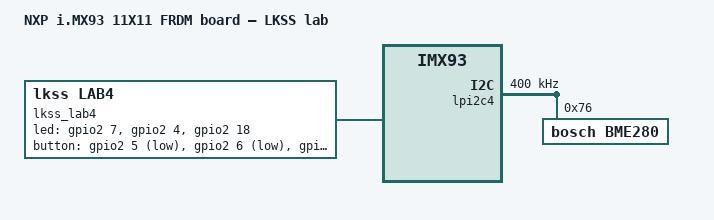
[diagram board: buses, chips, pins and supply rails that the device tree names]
// SPDX-License-Identifier: (GPL-2.0+ OR MIT)
/*
 * imx93-11x11-frdm-lkss.dts – LKSS lab device tree for NXP i.MX93 FRDM board
 *
 * Extends the upstream imx93-11x11-frdm.dts with two lab peripherals:
 *
 *   1. Bosch BME280 environmental sensor on LPI2C4
 *      – I2C address: 0x76 (SDO tied to GND)
 *      – SDA: GPIO_IO02 / EXT2 pin 3
 *      – SCL: GPIO_IO03 / EXT2 pin 5
 *
 *   2. Three GPIO-controlled LEDs (active-high, 220 Ω series resistor)
 *      – LED0 (red):   GPIO_IO07 / GPIO2_IO07 / EXT2 pin 26
 *      – LED1 (green): GPIO_IO04 / GPIO2_IO04 / EXT2 pin  7
 *      – LED2 (blue):  GPIO_IO18 / GPIO2_IO18 / EXT2 pin 12
 *
 *   3. Four GPIO push-buttons (active-low, external pull-ups to 3V3 required)
 *      – BTN1: GPIO_IO05 / GPIO2_IO05 / EXT2 pin 29
 *      – BTN2: GPIO_IO06 / GPIO2_IO06 / EXT2 pin 31
 *      – BTN3: GPIO_IO00 / GPIO2_IO00 / EXT2 pin 27
 *      – BTN4: GPIO_IO01 / GPIO2_IO01 / EXT2 pin 28
 *
 * Build:
 *   Add 'dtb-$(CONFIG_ARCH_MXC) += imx93-11x11-frdm-lkss.dtb' to
 *   arch/arm64/boot/dts/freescale/Makefile and rebuild with:
 *     make dtbs ARCH=arm64 CROSS_COMPILE=aarch64-linux-gnu-
 */

/dts-v1/;

#include "imx93-11x11-frdm.dts"

/ {
	model = "NXP i.MX93 11X11 FRDM board – LKSS lab";
	compatible = "fsl,imx93-11x11-frdm-lkss", "fsl,imx93-11x11-frdm", "fsl,imx93";

	/*
	 * lkss-lab4 – Lab 4 platform device (platform_gpio.ko).
	 *
	 * led-gpios and button-gpios use the GPIO descriptor consumer API:
	 * property "<name>-gpios", driver calls devm_gpiod_get_index(dev, "<name>", idx, flags).
	 * GPIO_ACTIVE_HIGH/LOW encodes polarity; gpiod handles inversion automatically.
	 */
	lkss_lab4: lkss-lab4 {
		compatible = "lkss,lab4";

		led-gpios = <&gpio2  7 GPIO_ACTIVE_HIGH>,  /* LED0 red   / pin 26 */
		            <&gpio2  4 GPIO_ACTIVE_HIGH>,  /* LED1 green / pin  7 */
		            <&gpio2 18 GPIO_ACTIVE_HIGH>;  /* LED2 blue  / pin 12 */

		/*
		 * Active-low: pressing pulls the line to GND.
		 * External 10 kΩ pull-ups to 3V3 required on each line.
		 */
		button-gpios = <&gpio2 5 GPIO_ACTIVE_LOW>,   /* BTN1 / pin 29 */
		               <&gpio2 6 GPIO_ACTIVE_LOW>,   /* BTN2 / pin 31 */
		               <&gpio2 0 GPIO_ACTIVE_LOW>,   /* BTN3 / pin 27 */
		               <&gpio2 1 GPIO_ACTIVE_LOW>;   /* BTN4 / pin 28 */

		pinctrl-names = "default";
		pinctrl-0 = <&pinctrl_lkss_gpio>;
		status = "okay";
	};

	/*
	 * lkss-gpio – reference implementation (lkss_gpio.ko, simple on/off).
	 * Disabled: lkss-lab4 claims the same GPIO lines.
	 * To use: set lkss-lab4 status = "disabled" and this to "okay".
	 */
	lkss_gpio: lkss-gpio {
		compatible = "lkss,gpio-demo";

		led-gpios = <&gpio2  7 GPIO_ACTIVE_HIGH>,  /* LED0 red   / pin 26 */
		            <&gpio2  4 GPIO_ACTIVE_HIGH>,  /* LED1 green / pin  7 */
		            <&gpio2 18 GPIO_ACTIVE_HIGH>;  /* LED2 blue  / pin 12 */

		button-gpios = <&gpio2 5 GPIO_ACTIVE_LOW>,   /* BTN1 / pin 29 */
		               <&gpio2 6 GPIO_ACTIVE_LOW>,   /* BTN2 / pin 31 */
		               <&gpio2 0 GPIO_ACTIVE_LOW>,   /* BTN3 / pin 27 */
		               <&gpio2 1 GPIO_ACTIVE_LOW>;   /* BTN4 / pin 28 */

		pinctrl-names = "default";
		pinctrl-0 = <&pinctrl_lkss_gpio>;
		status = "disabled";
	};
};

/* ── BME280 sensor on LPI2C4 ─────────────────────────────────────────────── */

&lpi2c4 {
	clock-frequency = <400000>;
	pinctrl-names = "default";
	pinctrl-0 = <&pinctrl_lpi2c4>;
	status = "okay";

	bme280: bme280@76 {
		compatible = "bosch,bme280";
		reg = <0x76>;
	};
};

/* ── Pin multiplexing ────────────────────────────────────────────────────── */
/*
 * Config 0x31e: medium drive strength, fast slew rate, no open-drain.
 * Suits both push-pull output (LEDs) and input (buttons).
 * Buttons require external 10 kΩ pull-ups — SoC internal pulls not enabled.
 */
&iomuxc {
	pinctrl_lkss_gpio: lkss-gpiogrp {
		fsl,pins = <
			/* LED outputs */
			MX93_PAD_GPIO_IO07__GPIO2_IO07		0x31e  /* LED0 red   / pin 26 */
			MX93_PAD_GPIO_IO04__GPIO2_IO04		0x31e  /* LED1 green / pin  7 */
			MX93_PAD_GPIO_IO18__GPIO2_IO18		0x31e  /* LED2 blue  / pin 12 */

			/* Button inputs, external pull-ups required */
			MX93_PAD_GPIO_IO05__GPIO2_IO05		0x31e  /* BTN1 / pin 29 */
			MX93_PAD_GPIO_IO06__GPIO2_IO06		0x31e  /* BTN2 / pin 31 */
			MX93_PAD_GPIO_IO00__GPIO2_IO00		0x31e  /* BTN3 / pin 27 */
			MX93_PAD_GPIO_IO01__GPIO2_IO01		0x31e  /* BTN4 / pin 28 */
		>;
	};
};
